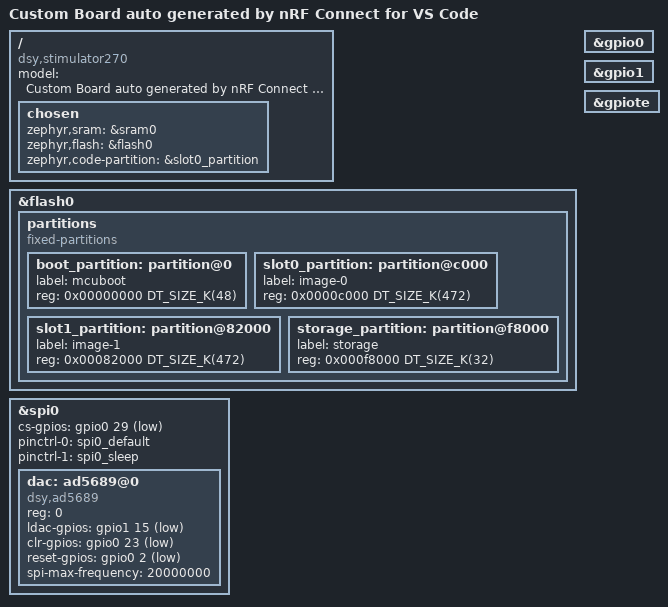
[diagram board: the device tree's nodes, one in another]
/dts-v1/;
#include <nordic/nrf52840_qfaa.dtsi>
#include "stimulator270-pinctrl.dtsi"

/ {
	model = "Custom Board auto generated by nRF Connect for VS Code";
	compatible = "dsy,stimulator270";

	chosen {
		zephyr,sram = &sram0;
		zephyr,flash = &flash0;
		zephyr,code-partition = &slot0_partition;
	};
};

&flash0 {
	partitions {
		compatible = "fixed-partitions";
		#address-cells = <1>;
		#size-cells = <1>;

		boot_partition: partition@0 {
			label = "mcuboot";
			reg = <0x00000000 DT_SIZE_K(48)>;
		};

		slot0_partition: partition@c000 {
			label = "image-0";
			reg = <0x0000c000 DT_SIZE_K(472)>;
		};

		slot1_partition: partition@82000 {
			label = "image-1";
			reg = <0x00082000 DT_SIZE_K(472)>;
		};

		storage_partition: partition@f8000 {
			label = "storage";
			reg = <0x000f8000 DT_SIZE_K(32)>;
		};
	};
};

&spi0 {
	status = "okay";
	pinctrl-names = "default", "sleep";
	cs-gpios = <&gpio0 29 GPIO_ACTIVE_LOW>;
	pinctrl-0 = <&spi0_default>;
	pinctrl-1 = <&spi0_sleep>;
    dac: ad5689@0 {
        compatible = "dsy,ad5689";
        reg = <0>;                       /* CS0 */
        ldac-gpios  = <&gpio1 15 GPIO_ACTIVE_LOW>;
        clr-gpios   = <&gpio0 23 GPIO_ACTIVE_LOW>;
        reset-gpios = <&gpio0 2 GPIO_ACTIVE_LOW>;
        spi-max-frequency = <20000000>;  /* 20 MHz */
        status = "okay";
    };
};
&gpio0 { status = "okay"; };
&gpio1 { status = "okay"; };

&gpiote {
    status = "okay";
};
